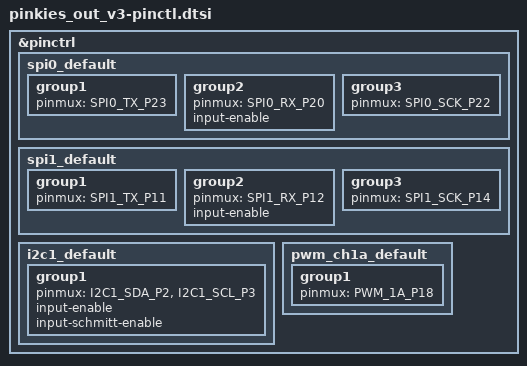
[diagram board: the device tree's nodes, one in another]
/*
 * Copyright (c) 2024, Sadek Baroudi
 * SPDX-License-Identifier: MIT
 */

#include <dt-bindings/pinctrl/rpi-pico-rp2040-pinctrl.h>

&pinctrl {
    // vik spi pinout
    spi0_default: spi0_default {
        group1 {
            pinmux = <SPI0_TX_P23>;
        };
        group2 {
            pinmux = <SPI0_RX_P20>;
            input-enable;
        };
        group3 {
            pinmux = <SPI0_SCK_P22>;
        };
    };

    // led spi pinout
    // doesn't matter what you set these to, not used, only CS pin is used
    // this is a ZMK hack to use SPI for leds
    spi1_default: spi1_default {
        group1 {
            pinmux = <SPI1_TX_P11>;
        };
        group2 {
            pinmux = <SPI1_RX_P12>;
            input-enable;
        };
        group3 {
            pinmux = <SPI1_SCK_P14>;
        };
    };
    
    // vik i2c pinout
    i2c1_default: i2c1_default {
        group1 {
            pinmux = <I2C1_SDA_P2>, <I2C1_SCL_P3>;
            input-enable;
            input-schmitt-enable;
        };
    };

	// for audio buzzer
	pwm_ch1a_default: pwm_ch1a_default {
		group1 {
			pinmux = <PWM_1A_P18>;
		};
	};
};
